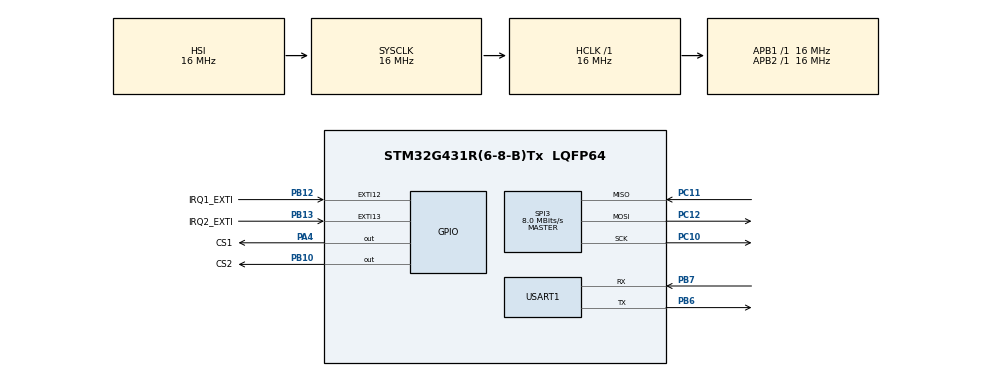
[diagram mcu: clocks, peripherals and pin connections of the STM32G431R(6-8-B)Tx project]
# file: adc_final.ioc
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Mcu.Family=STM32G4
Mcu.Name=STM32G431R(6-8-B)Tx
Mcu.Package=LQFP64
NVIC.PriorityGroup=NVIC_PRIORITYGROUP_4
PA4.GPIO_Label=CS1
PA4.Signal=GPIO_Output
PB10.GPIO_Label=CS2
PB10.Signal=GPIO_Output
PB12.GPIO_Label=IRQ1_EXTI
PB12.Signal=GPXTI12
PB13.GPIO_Label=IRQ2_EXTI
PB13.Signal=GPXTI13
PB6.Mode=Asynchronous
PB6.Signal=USART1_TX
PB7.Mode=Asynchronous
PB7.Signal=USART1_RX
PC10.Mode=Full_Duplex_Master
PC10.Signal=SPI3_SCK
PC11.Mode=Full_Duplex_Master
PC11.Signal=SPI3_MISO
PC12.Mode=Full_Duplex_Master
PC12.Signal=SPI3_MOSI
ProjectManager.HeapSize=0x200
ProjectManager.StackSize=0x400
ProjectManager.TargetToolchain=STM32CubeIDE
RCC.AHBFreq_Value=16000000
RCC.APB1Freq_Value=16000000
RCC.APB1TimFreq_Value=16000000
RCC.APB2Freq_Value=16000000
RCC.APB2TimFreq_Value=16000000
RCC.CortexFreq_Value=16000000
RCC.EXTERNAL_CLOCK_VALUE=12288000
RCC.HCLKFreq_Value=16000000
RCC.HSE_VALUE=8000000
RCC.HSI48_VALUE=48000000
RCC.HSI_VALUE=16000000
RCC.LSE_VALUE=32768
RCC.SYSCLKFreq_VALUE=16000000
RCC.USBFreq_Value=64000000
RCC.VCOOutputFreq_Value=128000000
SPI3.CalculateBaudRate=8.0 MBits/s
SPI3.DataSize=SPI_DATASIZE_8BIT
SPI3.Direction=SPI_DIRECTION_2LINES
SPI3.Mode=SPI_MODE_MASTER
SPI3.VirtualType=VM_MASTER
USART1.VirtualMode-Asynchronous=VM_ASYNC
VP_SYS_VS_DBSignals.Mode=DisableDeadBatterySignals
board=custom

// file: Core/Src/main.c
/* USER CODE BEGIN Header */
/**
  ******************************************************************************
  * @file           : main.c
  * @brief          : Main program body
  ******************************************************************************
  * @attention
  *
  * Copyright (c) 2025 STMicroelectronics.
  * All rights reserved.
  *
  * This software is licensed under terms that can be found in the LICENSE file
  * in the root directory of this software component.
  * If no LICENSE file comes with this software, it is provided AS-IS.
  *
  ******************************************************************************
  */
/* USER CODE END Header */
#include "main.h"
#include "adc_includes.h"

SPI_HandleTypeDef hspi3;

UART_HandleTypeDef huart1;

void SystemClock_Config(void);
static void MX_GPIO_Init(void);
static void MX_SPI3_Init(void);
static void MX_USART1_UART_Init(void);

int main(void)
{

  /* MCU Configuration--------------------------------------------------------*/

  /* Reset of all peripherals, Initializes the Flash interface and the Systick. */
  HAL_Init();

  /* Configure the system clock */
  SystemClock_Config();

  /* Initialize all configured peripherals */
  MX_GPIO_Init();
  MX_SPI3_Init();
  MX_USART1_UART_Init();
  /* USER CODE BEGIN 2 */
  adc_init();
  uart_standard_list();
  /* USER CODE END 2 */

  /* Infinite loop */
  /* USER CODE BEGIN WHILE */
#if 0
  // Marking the part of main while
#endif
  while (1)
  {
	  adc_test_routine();
	  // HAL_Delay(500);

    /* USER CODE END WHILE */

  }
}

void SystemClock_Config(void)
{
  RCC_OscInitTypeDef RCC_OscInitStruct = {0};
  RCC_ClkInitTypeDef RCC_ClkInitStruct = {0};

  /** Configure the main internal regulator output voltage
  */
  HAL_PWREx_ControlVoltageScaling(PWR_REGULATOR_VOLTAGE_SCALE1);

  /** Initializes the RCC Oscillators according to the specified parameters
  * in the RCC_OscInitTypeDef structure.
  */
  RCC_OscInitStruct.OscillatorType = RCC_OSCILLATORTYPE_HSI;
  RCC_OscInitStruct.HSIState = RCC_HSI_ON;
  RCC_OscInitStruct.HSICalibrationValue = RCC_HSICALIBRATION_DEFAULT;
  RCC_OscInitStruct.PLL.PLLState = RCC_PLL_NONE;
  if (HAL_RCC_OscConfig(&RCC_OscInitStruct) != HAL_OK)
  {
    Error_Handler();
  }

  /** Initializes the CPU, AHB and APB buses clocks
  */
  RCC_ClkInitStruct.ClockType = RCC_CLOCKTYPE_HCLK|RCC_CLOCKTYPE_SYSCLK
                              |RCC_CLOCKTYPE_PCLK1|RCC_CLOCKTYPE_PCLK2;
  RCC_ClkInitStruct.SYSCLKSource = RCC_SYSCLKSOURCE_HSI;
  RCC_ClkInitStruct.AHBCLKDivider = RCC_SYSCLK_DIV1;
  RCC_ClkInitStruct.APB1CLKDivider = RCC_HCLK_DIV1;
  RCC_ClkInitStruct.APB2CLKDivider = RCC_HCLK_DIV1;

  if (HAL_RCC_ClockConfig(&RCC_ClkInitStruct, FLASH_LATENCY_0) != HAL_OK)
  {
    Error_Handler();
  }
}

static void MX_SPI3_Init(void)
{

  /* SPI3 parameter configuration*/
  hspi3.Instance = SPI3;
  hspi3.Init.Mode = SPI_MODE_MASTER;
  hspi3.Init.Direction = SPI_DIRECTION_2LINES;
  hspi3.Init.DataSize = SPI_DATASIZE_8BIT;
  hspi3.Init.CLKPolarity = SPI_POLARITY_LOW;
  hspi3.Init.CLKPhase = SPI_PHASE_1EDGE;
  hspi3.Init.NSS = SPI_NSS_SOFT;
  hspi3.Init.BaudRatePrescaler = SPI_BAUDRATEPRESCALER_2;
  hspi3.Init.FirstBit = SPI_FIRSTBIT_MSB;
  hspi3.Init.TIMode = SPI_TIMODE_DISABLE;
  hspi3.Init.CRCCalculation = SPI_CRCCALCULATION_DISABLE;
  hspi3.Init.CRCPolynomial = 7;
  hspi3.Init.CRCLength = SPI_CRC_LENGTH_DATASIZE;
  hspi3.Init.NSSPMode = SPI_NSS_PULSE_ENABLE;
  if (HAL_SPI_Init(&hspi3) != HAL_OK)
  {
    Error_Handler();
  }

}

static void MX_USART1_UART_Init(void)
{

  huart1.Instance = USART1;
  huart1.Init.BaudRate = 115200;
  huart1.Init.WordLength = UART_WORDLENGTH_8B;
  huart1.Init.StopBits = UART_STOPBITS_1;
  huart1.Init.Parity = UART_PARITY_NONE;
  huart1.Init.Mode = UART_MODE_TX_RX;
  huart1.Init.HwFlowCtl = UART_HWCONTROL_NONE;
  huart1.Init.OverSampling = UART_OVERSAMPLING_16;
  huart1.Init.OneBitSampling = UART_ONE_BIT_SAMPLE_DISABLE;
  huart1.Init.ClockPrescaler = UART_PRESCALER_DIV1;
  huart1.AdvancedInit.AdvFeatureInit = UART_ADVFEATURE_NO_INIT;
  if (HAL_UART_Init(&huart1) != HAL_OK)
  {
    Error_Handler();
  }
  if (HAL_UARTEx_SetTxFifoThreshold(&huart1, UART_TXFIFO_THRESHOLD_1_8) != HAL_OK)
  {
    Error_Handler();
  }
  if (HAL_UARTEx_SetRxFifoThreshold(&huart1, UART_RXFIFO_THRESHOLD_1_8) != HAL_OK)
  {
    Error_Handler();
  }
  if (HAL_UARTEx_DisableFifoMode(&huart1) != HAL_OK)
  {
    Error_Handler();
  }

}

static void MX_GPIO_Init(void)
{
  GPIO_InitTypeDef GPIO_InitStruct = {0};

  /* GPIO Ports Clock Enable */
  __HAL_RCC_GPIOA_CLK_ENABLE();
  __HAL_RCC_GPIOB_CLK_ENABLE();
  __HAL_RCC_GPIOC_CLK_ENABLE();

  /*Configure GPIO pin Output Level */
  HAL_GPIO_WritePin(CS1_GPIO_Port, CS1_Pin, GPIO_PIN_RESET);

  /*Configure GPIO pin Output Level */
  HAL_GPIO_WritePin(CS2_GPIO_Port, CS2_Pin, GPIO_PIN_RESET);

  /*Configure GPIO pin : CS1_Pin */
  GPIO_InitStruct.Pin = CS1_Pin;
  GPIO_InitStruct.Mode = GPIO_MODE_OUTPUT_PP;
  GPIO_InitStruct.Pull = GPIO_NOPULL;
  GPIO_InitStruct.Speed = GPIO_SPEED_FREQ_LOW;
  HAL_GPIO_Init(CS1_GPIO_Port, &GPIO_InitStruct);

  /*Configure GPIO pin : CS2_Pin */
  GPIO_InitStruct.Pin = CS2_Pin;
  GPIO_InitStruct.Mode = GPIO_MODE_OUTPUT_PP;
  GPIO_InitStruct.Pull = GPIO_NOPULL;
  GPIO_InitStruct.Speed = GPIO_SPEED_FREQ_LOW;
  HAL_GPIO_Init(CS2_GPIO_Port, &GPIO_InitStruct);

  /*Configure GPIO pins : IRQ1_EXTI_Pin IRQ2_EXTI_Pin */
  GPIO_InitStruct.Pin = IRQ1_EXTI_Pin|IRQ2_EXTI_Pin;
  GPIO_InitStruct.Mode = GPIO_MODE_IT_RISING;
  GPIO_InitStruct.Pull = GPIO_NOPULL;
  HAL_GPIO_Init(GPIOB, &GPIO_InitStruct);

}

void Error_Handler(void)
{
  __disable_irq();
  while (1)
  {
  }
}
